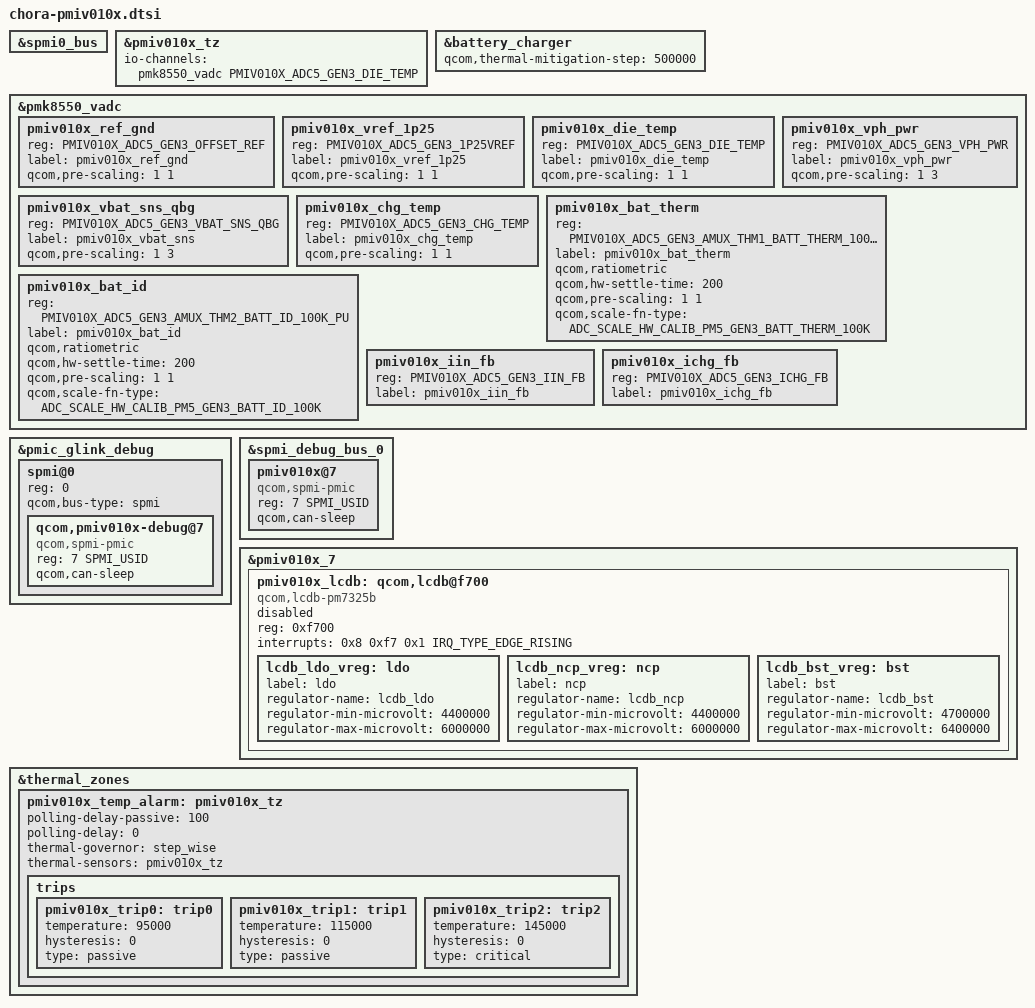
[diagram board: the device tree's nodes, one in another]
// SPDX-License-Identifier: BSD-3-Clause
/*
 * Copyright (c) Qualcomm Technologies, Inc. and/or its subsidiaries.
 */

#include <dt-bindings/iio/qcom,spmi-vadc.h>
#include <dt-bindings/iio/qcom,spmi-adc5-gen3-pmiv010x.h>

&spmi0_bus {
	#include "pmiv010x.dtsi"
};

&pmiv010x_tz {
	io-channels = <&pmk8550_vadc PMIV010X_ADC5_GEN3_DIE_TEMP>;
	io-channel-names = "thermal";
};

&battery_charger {
	#cooling-cells = <2>;
	qcom,thermal-mitigation-step = <500000>;
};

&pmk8550_vadc {
	pmiv010x_ref_gnd {
		reg = <PMIV010X_ADC5_GEN3_OFFSET_REF>;
		label = "pmiv010x_ref_gnd";
		qcom,pre-scaling = <1 1>;
	};

	pmiv010x_vref_1p25 {
		reg = <PMIV010X_ADC5_GEN3_1P25VREF>;
		label = "pmiv010x_vref_1p25";
		qcom,pre-scaling = <1 1>;
	};

	pmiv010x_die_temp {
		reg = <PMIV010X_ADC5_GEN3_DIE_TEMP>;
		label = "pmiv010x_die_temp";
		qcom,pre-scaling = <1 1>;
	};

	pmiv010x_vph_pwr {
		reg = <PMIV010X_ADC5_GEN3_VPH_PWR>;
		label = "pmiv010x_vph_pwr";
		qcom,pre-scaling = <1 3>;
	};

	pmiv010x_vbat_sns_qbg {
		reg = <PMIV010X_ADC5_GEN3_VBAT_SNS_QBG>;
		label = "pmiv010x_vbat_sns";
		qcom,pre-scaling = <1 3>;
	};

	pmiv010x_chg_temp {
		reg = <PMIV010X_ADC5_GEN3_CHG_TEMP>;
		label = "pmiv010x_chg_temp";
		qcom,pre-scaling = <1 1>;
	};

	pmiv010x_bat_therm {
		reg = <PMIV010X_ADC5_GEN3_AMUX_THM1_BATT_THERM_100K_PU>;
		label = "pmiv010x_bat_therm";
		qcom,ratiometric;
		qcom,hw-settle-time = <200>;
		qcom,pre-scaling = <1 1>;
		qcom,scale-fn-type = <ADC_SCALE_HW_CALIB_PM5_GEN3_BATT_THERM_100K>;
	};

	pmiv010x_bat_id {
		reg = <PMIV010X_ADC5_GEN3_AMUX_THM2_BATT_ID_100K_PU>;
		label = "pmiv010x_bat_id";
		qcom,ratiometric;
		qcom,hw-settle-time = <200>;
		qcom,pre-scaling = <1 1>;
		qcom,scale-fn-type = <ADC_SCALE_HW_CALIB_PM5_GEN3_BATT_ID_100K>;
	};

	pmiv010x_iin_fb {
		reg = <PMIV010X_ADC5_GEN3_IIN_FB>;
		label = "pmiv010x_iin_fb";
	};

	pmiv010x_ichg_fb {
		reg = <PMIV010X_ADC5_GEN3_ICHG_FB>;
		label = "pmiv010x_ichg_fb";
	};
};

&pmic_glink_debug {
	spmi@0 {
		reg = <0>;
		#address-cells = <2>;
		#size-cells = <0>;
		qcom,bus-type = "spmi";

		qcom,pmiv010x-debug@7 {
			compatible = "qcom,spmi-pmic";
			reg = <7 SPMI_USID>;
			qcom,can-sleep;
		};
	};
};

&spmi_debug_bus_0 {
	pmiv010x@7 {
		compatible = "qcom,spmi-pmic";
		reg = <7 SPMI_USID>;
		#address-cells = <2>;
		#size-cells = <0>;
		qcom,can-sleep;
	};
};

&pmiv010x_7 {
	pmiv010x_lcdb: qcom,lcdb@f700 {
			compatible = "qcom,lcdb-pm7325b";
			#address-cells = <1>;
			#size-cells = <0>;
			reg = <0xf700>;
			interrupts = <0x8 0xf7 0x1 IRQ_TYPE_EDGE_RISING>;
			interrupt-names = "sc-irq";
			status = "disabled";

			lcdb_ldo_vreg: ldo {
				label = "ldo";
				regulator-name = "lcdb_ldo";
				regulator-min-microvolt = <4400000>;
				regulator-max-microvolt = <6000000>;
			};

			lcdb_ncp_vreg: ncp {
				label = "ncp";
				regulator-name = "lcdb_ncp";
				regulator-min-microvolt = <4400000>;
				regulator-max-microvolt = <6000000>;
			};

			lcdb_bst_vreg: bst {
				label = "bst";
				regulator-name = "lcdb_bst";
				regulator-min-microvolt = <4700000>;
				regulator-max-microvolt = <6400000>;
			};
		};
};

&thermal_zones {
	pmiv010x_temp_alarm: pmiv010x_tz {
		polling-delay-passive = <100>;
		polling-delay = <0>;
		thermal-governor = "step_wise";
		thermal-sensors = <&pmiv010x_tz>;
		trips {
			pmiv010x_trip0: trip0 {
				temperature = <95000>;
				hysteresis = <0>;
				type = "passive";
			};

			pmiv010x_trip1: trip1 {
				temperature = <115000>;
				hysteresis = <0>;
				type = "passive";
			};

			pmiv010x_trip2: trip2 {
				temperature = <145000>;
				hysteresis = <0>;
				type = "critical";
			};
		};
	};
};
